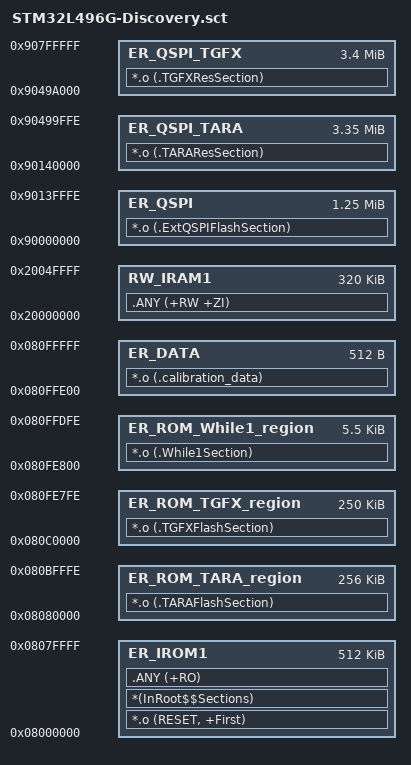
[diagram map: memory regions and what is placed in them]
; *************************************************************
; *** Scatter-Loading Description File generated by uVision ***
; *************************************************************

LR_IROM1 0x08000000 0x100000  {    ; load region size_region
  ER_IROM1 0x08000000 0x80000 {  ; load address = execution address
   *.o (RESET, +First)
   *(InRoot$$Sections)
   .ANY (+RO)
  }
  
   RW_IRAM1 0x20000000 0x00050000  {  ; RW data
   .ANY (+RW +ZI)
  }
}

LR_ROM_TARA_region 0x08080000 0x3FFFF {
ER_ROM_TARA_region 0x08080000 0x3FFFF {
   *.o (.TARAFlashSection)
  }
  }

  
LR_ROM_TGFX_region 0x080C0000 0x3E7FF {
ER_ROM_TGFX_region 0x080C0000 0x3E7FF {
   *.o (.TGFXFlashSection)
  }
  }


LR_ROM_While1_region 0x080FE800 0x15FF  {
ER_ROM_While1_region 0x080FE800 0x15FF  {
   *.o (.While1Section)
  }
  }

LR_DATA 0x080FFE00 0x200 {
  ER_DATA 0x080FFE00 0x200 { 
  *.o (.calibration_data) 
  }
  }
  
LR_QSPI 0x90000000 0x13FFFF {
ER_QSPI 0x90000000 0x13FFFF {
*.o (.ExtQSPIFlashSection)
}
}

LR_QSPI_TARA 0x90140000 0x359FFF {
ER_QSPI_TARA  0x90140000 0x359FFF {
*.o (.TARAResSection)
}
}

LR_QSPI_TGFX 0x9049A000 0x366000 {
ER_QSPI_TGFX 0x9049A000  0x366000 {
*.o (.TGFXResSection)
}
}




